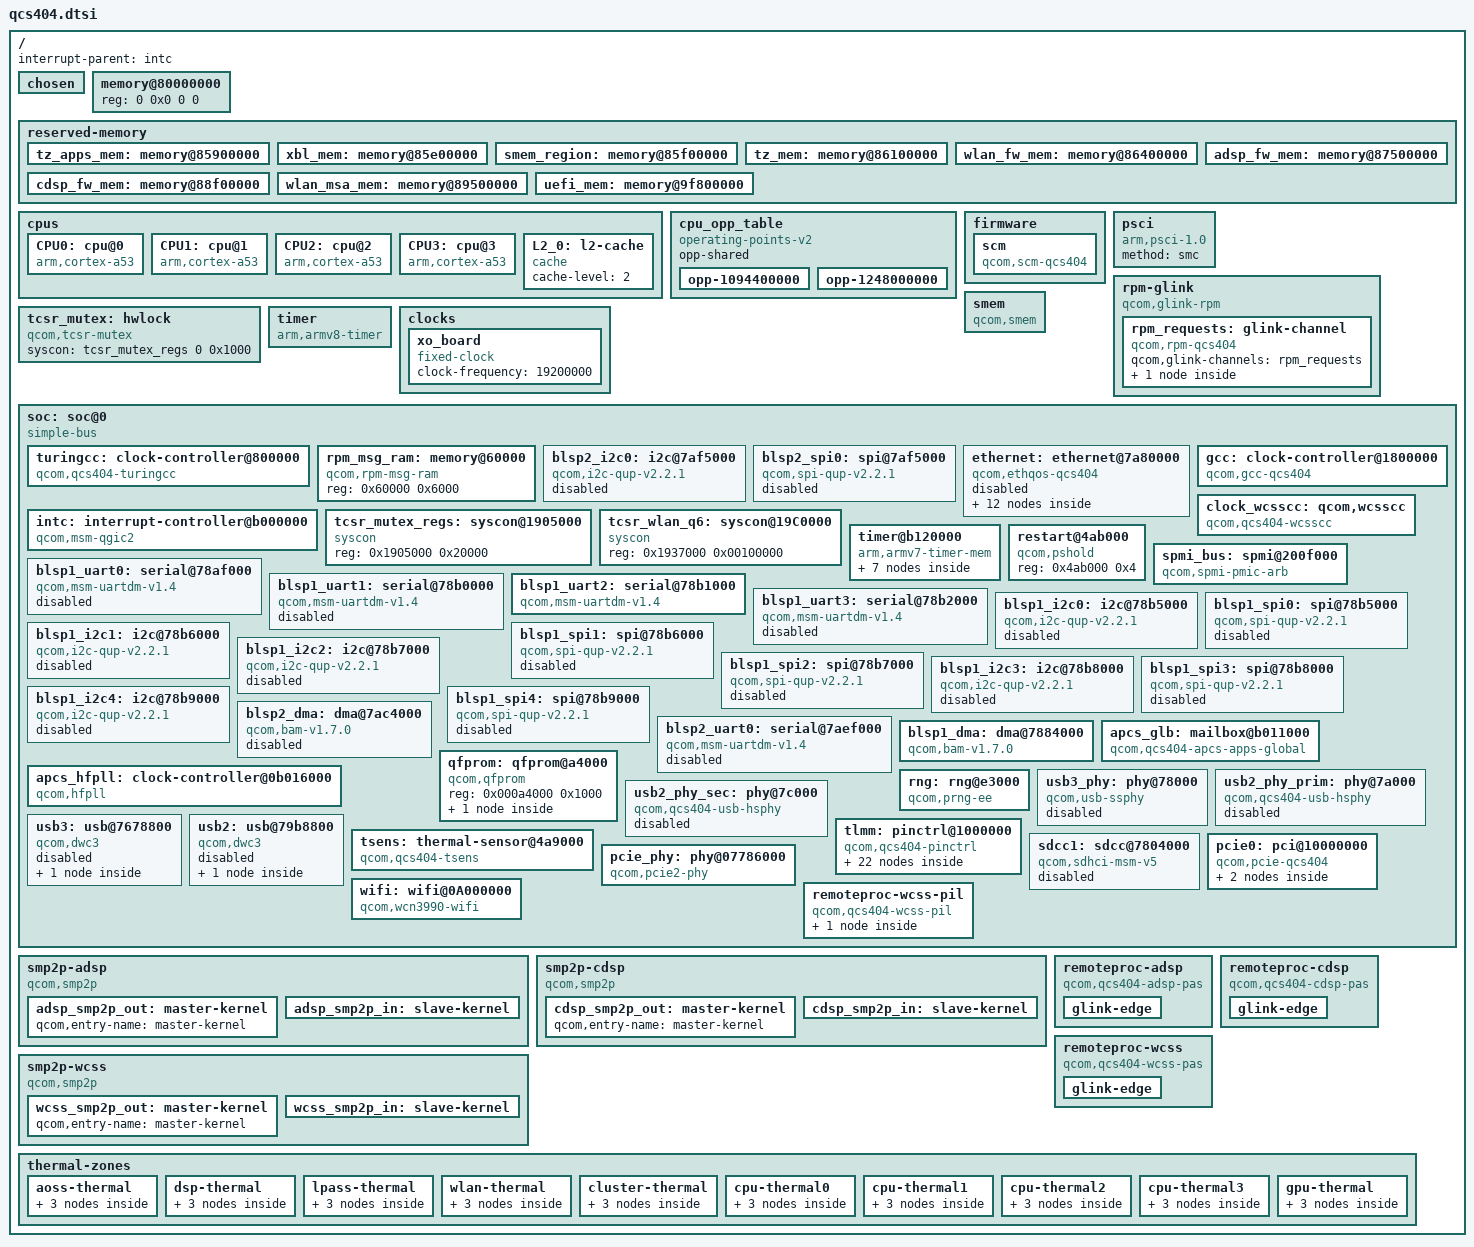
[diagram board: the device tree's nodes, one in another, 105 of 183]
// SPDX-License-Identifier: GPL-2.0
// Copyright (c) 2018, Linaro Limited

#include <dt-bindings/interrupt-controller/arm-gic.h>
#include <dt-bindings/clock/qcom,gcc-qcs404.h>
#include <dt-bindings/gpio/gpio.h>
#include <dt-bindings/clock/qcom,turingcc-qcs404.h>
#include <dt-bindings/clock/qcom,rpmcc.h>
#include <dt-bindings/clock/qcom,wcss-qcs404.h>

/ {
	interrupt-parent = <&intc>;

	#address-cells = <2>;
	#size-cells = <2>;

	chosen { };

	memory@80000000 {
		device_type = "memory";
		/* We expect the bootloader to fill in the reg */
		reg = <0 0x0 0 0>;
	};

	reserved-memory {
		#address-cells = <2>;
		#size-cells = <2>;
		ranges;

		tz_apps_mem: memory@85900000 {
			reg = <0 0x85900000 0 0x500000>;
			no-map;
		};

		xbl_mem: memory@85e00000 {
			reg = <0 0x85e00000 0 0x100000>;
			no-map;
		};

		smem_region: memory@85f00000 {
			reg = <0 0x85f00000 0 0x200000>;
			no-map;
		};

		tz_mem: memory@86100000 {
			reg = <0 0x86100000 0 0x300000>;
			no-map;
		};

		wlan_fw_mem: memory@86400000 {
			reg = <0 0x86400000 0 0x1100000>;
			no-map;
		};

		adsp_fw_mem: memory@87500000 {
			reg = <0 0x87500000 0 0x1a00000>;
			no-map;
		};

		cdsp_fw_mem: memory@88f00000 {
			reg = <0 0x88f00000 0 0x600000>;
			no-map;
		};

		wlan_msa_mem: memory@89500000 {
			reg = <0 0x89500000 0 0x100000>;
			no-map;
		};

		uefi_mem: memory@9f800000 {
			reg = <0 0x9f800000 0 0x800000>;
			no-map;
		};
	};

	cpus {
		#address-cells = <1>;
		#size-cells = <0>;

		CPU0: cpu@0 {
			device_type = "cpu";
			compatible = "arm,cortex-a53";
			reg = <0x100>;
			enable-method = "psci";
			next-level-cache = <&L2_0>;
			#cooling-cells= <2>;
			clocks = <&apcs_glb>;
			operating-points-v2 = <&cpu_opp_table>;
			cpu-supply = <&pms405_s3>;
		};

		CPU1: cpu@1 {
			device_type = "cpu";
			compatible = "arm,cortex-a53";
			reg = <0x101>;
			enable-method = "psci";
			next-level-cache = <&L2_0>;
			#cooling-cells= <2>;
			clocks = <&apcs_glb>;
			operating-points-v2 = <&cpu_opp_table>;
			cpu-supply = <&pms405_s3>;
		};

		CPU2: cpu@2 {
			device_type = "cpu";
			compatible = "arm,cortex-a53";
			reg = <0x102>;
			enable-method = "psci";
			next-level-cache = <&L2_0>;
			#cooling-cells= <2>;
			clocks = <&apcs_glb>;
			operating-points-v2 = <&cpu_opp_table>;
			cpu-supply = <&pms405_s3>;
		};

		CPU3: cpu@3 {
			device_type = "cpu";
			compatible = "arm,cortex-a53";
			reg = <0x103>;
			enable-method = "psci";
			next-level-cache = <&L2_0>;
			#cooling-cells= <2>;
			clocks = <&apcs_glb>;
			operating-points-v2 = <&cpu_opp_table>;
			cpu-supply = <&pms405_s3>;
		};

		L2_0: l2-cache {
			compatible = "cache";
			cache-level = <2>;
		};
	};

	cpu_opp_table: cpu_opp_table {
		compatible = "operating-points-v2";
		opp-shared;

		opp-1094400000 {
			opp-hz = /bits/ 64 <1094400000>;
			opp-microvolt = <1224000 1224000 1224000>;
		};
		opp-1248000000 {
			opp-hz = /bits/ 64 <1248000000>;
			opp-microvolt = <1288000 1288000 1288000>;
		};
	};

	firmware {
		scm: scm {
			compatible = "qcom,scm-qcs404", "qcom,scm";
			#reset-cells = <1>;
		};
	};

	psci {
		compatible = "arm,psci-1.0";
		method = "smc";
	};

	rpm-glink {
		compatible = "qcom,glink-rpm";

		interrupts = <GIC_SPI 168 IRQ_TYPE_EDGE_RISING>;
		qcom,rpm-msg-ram = <&rpm_msg_ram>;
		mboxes = <&apcs_glb 0>;

		rpm_requests: glink-channel {
			compatible = "qcom,rpm-qcs404";
			qcom,glink-channels = "rpm_requests";

			rpmcc: clock-controller {
				compatible = "qcom,rpmcc-qcs404";
				#clock-cells = <1>;
			};
		};
	};

	smem {
		compatible = "qcom,smem";

		memory-region = <&smem_region>;
		qcom,rpm-msg-ram = <&rpm_msg_ram>;

		hwlocks = <&tcsr_mutex 3>;
	};

	tcsr_mutex: hwlock {
		compatible = "qcom,tcsr-mutex";
		syscon = <&tcsr_mutex_regs 0 0x1000>;
		#hwlock-cells = <1>;
	};

	timer {
		compatible = "arm,armv8-timer";
		interrupts = <GIC_PPI 2 0xff08>,
			     <GIC_PPI 3 0xff08>,
			     <GIC_PPI 4 0xff08>,
			     <GIC_PPI 1 0xff08>;
	};

	clocks {
		xo_board: xo_board {
			compatible = "fixed-clock";
			#clock-cells = <0>;
			clock-frequency = <19200000>;
		};
	};

	soc: soc@0 {
		#address-cells = <1>;
		#size-cells = <1>;
		ranges = <0 0 0 0xffffffff>;
		compatible = "simple-bus";

		turingcc: clock-controller@800000 {
			compatible = "qcom,qcs404-turingcc";
			reg = <0x00800000 0x30000>;
			clocks = <&gcc GCC_CDSP_CFG_AHB_CLK>;

			#clock-cells = <1>;
			#reset-cells = <1>;
		};

		rpm_msg_ram: memory@60000 {
			compatible = "qcom,rpm-msg-ram";
			reg = <0x60000 0x6000>;
		};

		blsp2_i2c0: i2c@7af5000 {
			compatible = "qcom,i2c-qup-v2.2.1";
			reg = <0x07af5000 0x600>;
			interrupts = <GIC_SPI 299 IRQ_TYPE_LEVEL_HIGH>;
			clocks = <&gcc GCC_BLSP2_AHB_CLK>,
				<&gcc GCC_BLSP2_QUP0_I2C_APPS_CLK>;
			clock-names = "iface", "core";
			pinctrl-names = "default";
			pinctrl-0 = <&blsp2_i2c0_default>;
			#address-cells = <1>;
			#size-cells = <0>;
			status = "disabled";
		};

		blsp2_spi0: spi@7af5000 {
			compatible = "qcom,spi-qup-v2.2.1";
			reg = <0x07af5000 0x600>;
			interrupts = <GIC_SPI 299 IRQ_TYPE_LEVEL_HIGH>;
			clocks = <&gcc GCC_BLSP2_AHB_CLK>,
				<&gcc GCC_BLSP2_QUP0_SPI_APPS_CLK>;
			clock-names = "iface", "core";
			pinctrl-names = "default";
			pinctrl-0 = <&blsp2_spi0_default>;
			#address-cells = <1>;
			#size-cells = <0>;
			status = "disabled";
		};

		ethernet: ethernet@7a80000 {
			compatible = "qcom,ethqos-qcs404";
			reg = <0x07a80000 0x10000>,
			        <0x07a96000 0x100>;
			reg-names = "stmmaceth", "rgmii";
			clock-names = "stmmaceth", "pclk", "ptp_ref", "rgmii";
			clocks = <&gcc GCC_ETH_AXI_CLK>,
				<&gcc GCC_ETH_SLAVE_AHB_CLK>,
				<&gcc GCC_ETH_PTP_CLK>,
				<&gcc GCC_ETH_RGMII_CLK>;
			interrupts = <GIC_SPI 56 IRQ_TYPE_LEVEL_HIGH>,
					<GIC_SPI 55 IRQ_TYPE_LEVEL_HIGH>;
			interrupt-names = "macirq", "eth_lpi";

			snps,axi-config = <&stmmac_axi_setup>;
			snps,mtl-rx-config = <&mtl_rx_setup>;
			snps,mtl-tx-config = <&mtl_tx_setup>;

			snps,txpbl = <8>;
			snps,rxpbl = <2>;
			snps,aal;
			snps,tso;

			rx-fifo-depth = <4096>;
			tx-fifo-depth = <4096>;
			snps,force_sf_dma_mode;
			status = "disabled";

			stmmac_axi_setup: stmmac-axi-config {
				snps,rd_osr_lmt = <2>;
				snps,blen = <0 0 0 0 16 8 4>;
			};
			mtl_rx_setup: rx-queues-config {
				snps,rx-queues-to-use = <4>;
				snps,rx-sched-sp;
				queue0 {
					snps,dcb-algorithm;
					snps,map-to-dma-channel = <0x0>;
					snps,priority = <0x0>;
				};
				queue1 {
					snps,dcb-algorithm;
					snps,map-to-dma-channel = <0x1>;
					snps,priority = <0x1>;
				};
				queue2 {
					snps,dcb-algorithm;
					snps,map-to-dma-channel = <0x2>;
					snps,priority = <0x1>;
				};
				queue3 {
					snps,dcb-algorithm;
					snps,map-to-dma-channel = <0x3>;
					snps,priority = <0x1>;
				};
			};

			mtl_tx_setup: tx-queues-config {
				snps,tx-queues-to-use = <5>;
				snps,tx-sched-wrr;
				queue0 {
					snps,weight = <0x10>;
					snps,dcb-algorithm;
					snps,priority = <0x0>;
					snps,map-to-dma-channel = <0x0>;
				};
				queue1 {
					snps,weight = <0x10>;
					snps,dcb-algorithm;
					snps,priority = <0x1>;
					snps,map-to-dma-channel = <0x1>;
				};
				queue2 {
					snps,weight = <0x10>;
					snps,dcb-algorithm;
					snps,priority = <0x1>;
					snps,map-to-dma-channel = <0x2>;
				};
				queue3 {
					snps,weight = <0x10>;
					snps,dcb-algorithm;
					snps,priority = <0x1>;
					snps,map-to-dma-channel = <0x3>;
				};
				queue4 {
					snps,weight = <0x10>;
					snps,dcb-algorithm;
					snps,priority = <0x1>;
					snps,map-to-dma-channel = <0x4>;
				};
			};
		};

		intc: interrupt-controller@b000000 {
			compatible = "qcom,msm-qgic2";
			interrupt-controller;
			#interrupt-cells = <3>;
			reg = <0x0b000000 0x1000>,
			      <0x0b002000 0x1000>;
		};

		gcc: clock-controller@1800000 {
			compatible = "qcom,gcc-qcs404";
			reg = <0x1800000 0x80000>;
			#clock-cells = <1>;
			#reset-cells = <1>;

			assigned-clocks = <&gcc GCC_APSS_AHB_CLK_SRC>;
			assigned-clock-rates = <19200000>;
			qcom,wcss-protected;
		};

		clock_wcsscc: qcom,wcsscc {
			compatible = "qcom,qcs404-wcsscc";
			reg = <0x07500000 0x4e000>, <0x07550000 0x8012>, <0x07400000 0x104>;
			reg-names = "wcss_q6sstop", "wcnss_tcsr", "wcss_qdsp6ss";
			#clock-cells = <1>;
			#reset-cells = <1>;
		};

		tcsr_mutex_regs: syscon@1905000 {
			compatible = "syscon";
			reg = <0x1905000 0x20000>;
		};

		tcsr_wlan_q6: syscon@19C0000 {
			compatible = "syscon";
			reg = <0x1937000 0x00100000>;
		};

		timer@b120000 {
			#address-cells = <1>;
			#size-cells = <1>;
			ranges;
			compatible = "arm,armv7-timer-mem";
			reg = <0xb120000 0x1000>;
			clock-frequency = <19200000>;

			frame@b121000 {
				frame-number = <0>;
				interrupts = <GIC_SPI 8 IRQ_TYPE_LEVEL_HIGH>,
					     <GIC_SPI 7 IRQ_TYPE_LEVEL_HIGH>;
				reg = <0xb121000 0x1000>,
				      <0xb122000 0x1000>;
			};

			frame@b123000 {
				frame-number = <1>;
				interrupts = <GIC_SPI 9 IRQ_TYPE_LEVEL_HIGH>;
				reg = <0xb123000 0x1000>;
				status = "disabled";
			};

			frame@b124000 {
				frame-number = <2>;
				interrupts = <GIC_SPI 10 IRQ_TYPE_LEVEL_HIGH>;
				reg = <0xb124000 0x1000>;
				status = "disabled";
			};

			frame@b125000 {
				frame-number = <3>;
				interrupts = <GIC_SPI 11 IRQ_TYPE_LEVEL_HIGH>;
				reg = <0xb125000 0x1000>;
				status = "disabled";
			};

			frame@b126000 {
				frame-number = <4>;
				interrupts = <GIC_SPI 12 IRQ_TYPE_LEVEL_HIGH>;
				reg = <0xb126000 0x1000>;
				status = "disabled";
			};

			frame@b127000 {
				frame-number = <5>;
				interrupts = <GIC_SPI 13 IRQ_TYPE_LEVEL_HIGH>;
				reg = <0xb127000 0x1000>;
				status = "disabled";
			};

			frame@b128000 {
				frame-number = <6>;
				interrupts = <GIC_SPI 14 IRQ_TYPE_LEVEL_HIGH>;
				reg = <0xb128000 0x1000>;
				status = "disabled";
			};
		};

		restart@4ab000 {
			compatible = "qcom,pshold";
			reg = <0x4ab000 0x4>;
		};

		spmi_bus: spmi@200f000 {
			compatible = "qcom,spmi-pmic-arb";
			reg = <0x200f000 0x001000>,
			      <0x2400000 0x800000>,
			      <0x2c00000 0x800000>,
			      <0x3800000 0x200000>,
			      <0x200a000 0x002100>;
			reg-names = "core", "chnls", "obsrvr", "intr", "cnfg";
			interrupt-names = "periph_irq";
			interrupts = <GIC_SPI 190 IRQ_TYPE_LEVEL_HIGH>;
			qcom,ee = <0>;
			qcom,channel = <0>;
			#address-cells = <2>;
			#size-cells = <0>;
			interrupt-controller;
			#interrupt-cells = <4>;
		};

		blsp1_uart0: serial@78af000 {
			compatible = "qcom,msm-uartdm-v1.4", "qcom,msm-uartdm";
			reg = <0x078af000 0x200>;
			interrupts = <GIC_SPI 107 IRQ_TYPE_LEVEL_HIGH>;
			clocks = <&gcc GCC_BLSP1_UART0_APPS_CLK>, <&gcc GCC_BLSP1_AHB_CLK>;
			clock-names = "core", "iface";
			dmas = <&blsp1_dma 1>, <&blsp1_dma 0>;
			dma-names = "rx", "tx";
			pinctrl-names = "default";
			pinctrl-0 = <&blsp1_uart0_default>;
			status = "disabled";
		};

		blsp1_uart1: serial@78b0000 {
			compatible = "qcom,msm-uartdm-v1.4", "qcom,msm-uartdm";
			reg = <0x078b0000 0x200>;
			interrupts = <GIC_SPI 108 IRQ_TYPE_LEVEL_HIGH>;
			clocks = <&gcc GCC_BLSP1_UART1_APPS_CLK>, <&gcc GCC_BLSP1_AHB_CLK>;
			clock-names = "core", "iface";
			dmas = <&blsp1_dma 3>, <&blsp1_dma 2>;
			dma-names = "rx", "tx";
			pinctrl-names = "default";
			pinctrl-0 = <&blsp1_uart1_default>;
			status = "disabled";
		};

		blsp1_uart2: serial@78b1000 {
			compatible = "qcom,msm-uartdm-v1.4", "qcom,msm-uartdm";
			reg = <0x78b1000 0x200>;
			interrupts = <GIC_SPI 118 IRQ_TYPE_LEVEL_HIGH>;
			clocks = <&gcc GCC_BLSP1_UART2_APPS_CLK>, <&gcc GCC_BLSP1_AHB_CLK>;
			clock-names = "core", "iface";
			dmas = <&blsp1_dma 5>, <&blsp1_dma 4>;
			dma-names = "rx", "tx";
			pinctrl-names = "default";
			pinctrl-0 = <&blsp1_uart2_default>;
			status = "okay";
		};

		blsp1_uart3: serial@78b2000 {
			compatible = "qcom,msm-uartdm-v1.4", "qcom,msm-uartdm";
			reg = <0x078b2000 0x200>;
			interrupts = <GIC_SPI 119 IRQ_TYPE_LEVEL_HIGH>;
			clocks = <&gcc GCC_BLSP1_UART3_APPS_CLK>, <&gcc GCC_BLSP1_AHB_CLK>;
			clock-names = "core", "iface";
			dmas = <&blsp1_dma 7>, <&blsp1_dma 6>;
			dma-names = "rx", "tx";
			status = "disabled";
		};

		blsp1_i2c0: i2c@78b5000 {
			compatible = "qcom,i2c-qup-v2.2.1";
			reg = <0x078b5000 0x600>;
			interrupts = <GIC_SPI 95 IRQ_TYPE_LEVEL_HIGH>;
			clocks = <&gcc GCC_BLSP1_AHB_CLK>,
				<&gcc GCC_BLSP1_QUP0_I2C_APPS_CLK>;
			clock-names = "iface", "core";
			pinctrl-names = "default";
			pinctrl-0 = <&blsp1_i2c0_default>;
			#address-cells = <1>;
			#size-cells = <0>;
			status = "disabled";
		};

		blsp1_spi0: spi@78b5000 {
			compatible = "qcom,spi-qup-v2.2.1";
			reg = <0x078b5000 0x600>;
			interrupts = <GIC_SPI 95 IRQ_TYPE_LEVEL_HIGH>;
			clocks = <&gcc GCC_BLSP1_AHB_CLK>,
				<&gcc GCC_BLSP1_QUP0_SPI_APPS_CLK>;
			clock-names = "iface", "core";
			pinctrl-names = "default";
			pinctrl-0 = <&blsp1_spi0_default>;
			#address-cells = <1>;
			#size-cells = <0>;
			status = "disabled";
		};

		blsp1_i2c1: i2c@78b6000 {
			compatible = "qcom,i2c-qup-v2.2.1";
			reg = <0x078b6000 0x600>;
			interrupts = <GIC_SPI 96 IRQ_TYPE_LEVEL_HIGH>;
			clocks = <&gcc GCC_BLSP1_AHB_CLK>,
				<&gcc GCC_BLSP1_QUP1_I2C_APPS_CLK>;
			clock-names = "iface", "core";
			pinctrl-names = "default";
			pinctrl-0 = <&blsp1_i2c1_default>;
			#address-cells = <1>;
			#size-cells = <0>;
			status = "disabled";
		};

		blsp1_spi1: spi@78b6000 {
			compatible = "qcom,spi-qup-v2.2.1";
			reg = <0x078b6000 0x600>;
			interrupts = <GIC_SPI 96 IRQ_TYPE_LEVEL_HIGH>;
			clocks = <&gcc GCC_BLSP1_AHB_CLK>,
				<&gcc GCC_BLSP1_QUP1_SPI_APPS_CLK>;
			clock-names = "iface", "core";
			pinctrl-names = "default";
			pinctrl-0 = <&blsp1_spi1_default>;
			#address-cells = <1>;
			#size-cells = <0>;
			status = "disabled";
		};

		blsp1_i2c2: i2c@78b7000 {
			compatible = "qcom,i2c-qup-v2.2.1";
			reg = <0x078b7000 0x600>;
			interrupts = <GIC_SPI 97 IRQ_TYPE_LEVEL_HIGH>;
			clocks = <&gcc GCC_BLSP1_AHB_CLK>,
				<&gcc GCC_BLSP1_QUP2_I2C_APPS_CLK>;
			clock-names = "iface", "core";
			pinctrl-names = "default";
			pinctrl-0 = <&blsp1_i2c2_default>;
			#address-cells = <1>;
			#size-cells = <0>;
			status = "disabled";
		};

		blsp1_spi2: spi@78b7000 {
			compatible = "qcom,spi-qup-v2.2.1";
			reg = <0x078b7000 0x600>;
			interrupts = <GIC_SPI 97 IRQ_TYPE_LEVEL_HIGH>;
			clocks = <&gcc GCC_BLSP1_AHB_CLK>,
				<&gcc GCC_BLSP1_QUP2_SPI_APPS_CLK>;
			clock-names = "iface", "core";
			pinctrl-names = "default";
			pinctrl-0 = <&blsp1_spi2_default>;
			#address-cells = <1>;
			#size-cells = <0>;
			status = "disabled";
		};

		blsp1_i2c3: i2c@78b8000 {
			compatible = "qcom,i2c-qup-v2.2.1";
			reg = <0x078b8000 0x600>;
			interrupts = <GIC_SPI 98 IRQ_TYPE_LEVEL_HIGH>;
			clocks = <&gcc GCC_BLSP1_AHB_CLK>,
				<&gcc GCC_BLSP1_QUP3_I2C_APPS_CLK>;
			clock-names = "iface", "core";
			pinctrl-names = "default";
			pinctrl-0 = <&blsp1_i2c3_default>;
			#address-cells = <1>;
			#size-cells = <0>;
			status = "disabled";
		};

		blsp1_spi3: spi@78b8000 {
			compatible = "qcom,spi-qup-v2.2.1";
			reg = <0x078b8000 0x600>;
			interrupts = <GIC_SPI 98 IRQ_TYPE_LEVEL_HIGH>;
			clocks = <&gcc GCC_BLSP1_AHB_CLK>,
				<&gcc GCC_BLSP1_QUP3_SPI_APPS_CLK>;
			clock-names = "iface", "core";
			pinctrl-names = "default";
			pinctrl-0 = <&blsp1_spi3_default>;
			#address-cells = <1>;
			#size-cells = <0>;
			status = "disabled";
		};

		blsp1_i2c4: i2c@78b9000 {
			compatible = "qcom,i2c-qup-v2.2.1";
			reg = <0x078b9000 0x600>;
			interrupts = <GIC_SPI 99 IRQ_TYPE_LEVEL_HIGH>;
			clocks = <&gcc GCC_BLSP1_AHB_CLK>,
				<&gcc GCC_BLSP1_QUP4_I2C_APPS_CLK>;
			clock-names = "iface", "core";
			pinctrl-names = "default";
			pinctrl-0 = <&blsp1_i2c4_default>;
			#address-cells = <1>;
			#size-cells = <0>;
			status = "disabled";
		};

		blsp1_spi4: spi@78b9000 {
			compatible = "qcom,spi-qup-v2.2.1";
			reg = <0x078b9000 0x600>;
			interrupts = <GIC_SPI 99 IRQ_TYPE_LEVEL_HIGH>;
			clocks = <&gcc GCC_BLSP1_AHB_CLK>,
				<&gcc GCC_BLSP1_QUP4_SPI_APPS_CLK>;
			clock-names = "iface", "core";
			pinctrl-names = "default";
			pinctrl-0 = <&blsp1_spi4_default>;
			#address-cells = <1>;
			#size-cells = <0>;
			status = "disabled";
		};

		blsp2_dma: dma@7ac4000 {
			compatible = "qcom,bam-v1.7.0";
			reg = <0x07ac4000 0x17000>;
			interrupts = <GIC_SPI 239 IRQ_TYPE_LEVEL_HIGH>;
			clocks = <&gcc GCC_BLSP2_AHB_CLK>;
			clock-names = "bam_clk";
			#dma-cells = <1>;
			qcom,controlled-remotely = <1>;
			qcom,ee = <0>;
			status = "disabled";
		};

		blsp2_uart0: serial@7aef000 {
			compatible = "qcom,msm-uartdm-v1.4", "qcom,msm-uartdm";
			reg = <0x07aef000 0x200>;
			interrupts = <GIC_SPI 297 IRQ_TYPE_LEVEL_HIGH>;
			clocks = <&gcc GCC_BLSP2_UART0_APPS_CLK>, <&gcc GCC_BLSP2_AHB_CLK>;
			clock-names = "core", "iface";
			dmas = <&blsp2_dma 1>, <&blsp2_dma 0>;
			dma-names = "rx", "tx";
			pinctrl-names = "default";
			pinctrl-0 = <&blsp2_uart0_default>;
			status = "disabled";
		};

		blsp1_dma: dma@7884000 {
			compatible = "qcom,bam-v1.7.0";
			reg = <0x07884000 0x25000>;
			interrupts = <GIC_SPI 238 IRQ_TYPE_LEVEL_HIGH>;
			clocks = <&gcc GCC_BLSP1_AHB_CLK>;
			clock-names = "bam_clk";
			#dma-cells = <1>;
			qcom,controlled-remotely = <1>;
			qcom,ee = <0>;

			status = "okay";
		};

		apcs_glb: mailbox@b011000 {
			compatible = "qcom,qcs404-apcs-apps-global", "syscon";
			reg = <0xb011000 0x1000>;
			#mbox-cells = <1>;
			clocks = <&gcc GCC_GPLL0_AO_OUT_MAIN>, <&apcs_hfpll>;
			clock-names = "aux", "pll";
			#clock-cells = <0>;
		};

		apcs_hfpll: clock-controller@0b016000 {
			compatible = "qcom,hfpll";
			reg = <0x0b016000 0x30>;
			#clock-cells = <0>;
			clock-output-names = "apcs_hfpll";
			clocks = <&xo_board>;
			clock-names = "xo";
		};

		qfprom: qfprom@a4000 {
			compatible = "qcom,qfprom";
			reg = <0x000a4000 0x1000>;
			#address-cells = <1>;
			#size-cells = <1>;
			tsens_caldata: caldata@d0 {
				reg = <0x1f8 0x14>;
			};
		};

		rng: rng@e3000 {
			compatible = "qcom,prng-ee";
			reg = <0x000e3000 0x1000>;
			clocks = <&gcc GCC_PRNG_AHB_CLK>;
			clock-names = "core";
		};

		usb3_phy: phy@78000 {
			compatible = "qcom,usb-ssphy";
			reg = <0x78000 0x400>;
			#phy-cells = <0>;
			clocks = <&rpmcc RPM_SMD_LN_BB_CLK>,
				<&gcc GCC_USB_HS_PHY_CFG_AHB_CLK>,
				<&gcc GCC_USB3_PHY_PIPE_CLK>;
			clock-names = "ref", "phy", "pipe";
			resets = <&gcc GCC_USB3_PHY_BCR>,
				<&gcc GCC_USB3PHY_PHY_BCR>;
			reset-names = "com", "phy";
			status = "disabled";
		};

		usb2_phy_prim: phy@7a000 {
			compatible = "qcom,qcs404-usb-hsphy";
			reg = <0x7a000 0x200>;
			#phy-cells = <0>;
			clocks = <&rpmcc RPM_SMD_LN_BB_CLK>,
				<&gcc GCC_USB_HS_PHY_CFG_AHB_CLK>,
				<&gcc GCC_USB2A_PHY_SLEEP_CLK>;
			clock-names = "ref", "phy", "sleep";
			resets = <&gcc GCC_USB_HS_PHY_CFG_AHB_BCR>,
				<&gcc GCC_USB2A_PHY_BCR>;
			reset-names = "phy", "por";
			status = "disabled";
		};

		usb2_phy_sec: phy@7c000 {
			compatible = "qcom,qcs404-usb-hsphy";
			reg = <0x7c000 0x200>;
			#phy-cells = <0>;
			clocks = <&rpmcc RPM_SMD_LN_BB_CLK>,
				<&gcc GCC_USB_HS_PHY_CFG_AHB_CLK>,
				<&gcc GCC_USB2A_PHY_SLEEP_CLK>;
			clock-names = "ref", "phy", "sleep";
			resets = <&gcc GCC_QUSB2_PHY_BCR>,
				<&gcc GCC_USB2_HS_PHY_ONLY_BCR>;
			reset-names = "phy", "por";
			status = "disabled";
		};

		usb3: usb@7678800 {
			compatible = "qcom,dwc3";
			reg = <0x07678800 0x400>;
			#address-cells = <1>;
			#size-cells = <1>;
			ranges;
			clocks = <&gcc GCC_USB30_MASTER_CLK>,
				<&gcc GCC_SYS_NOC_USB3_CLK>,
				<&gcc GCC_USB30_SLEEP_CLK>,
				<&gcc GCC_USB30_MOCK_UTMI_CLK>;
			clock-names = "core", "iface", "sleep", "mock_utmi";
			assigned-clocks = <&gcc GCC_USB20_MOCK_UTMI_CLK>,
					<&gcc GCC_USB30_MASTER_CLK>;
			assigned-clock-rates = <19200000>, <200000000>;
			status = "disabled";

			dwc3@7580000 {
				compatible = "snps,dwc3";
				reg = <0x07580000 0xcd00>;
				interrupts = <GIC_SPI 26 IRQ_TYPE_LEVEL_HIGH>;
				phys = <&usb2_phy_sec>, <&usb3_phy>;
				phy-names = "usb2-phy", "usb3-phy";
				snps,has-lpm-erratum;
				snps,hird-threshold = /bits/ 8 <0x10>;
				snps,usb3_lpm_capable;
				dr_mode = "host";
			};
		};

		usb2: usb@79b8800 {
			compatible = "qcom,dwc3";
			reg = <0x079b8800 0x400>;
			#address-cells = <1>;
			#size-cells = <1>;
			ranges;
			clocks = <&gcc GCC_USB_HS_SYSTEM_CLK>,
				<&gcc GCC_PCNOC_USB2_CLK>,
				<&gcc GCC_USB_HS_INACTIVITY_TIMERS_CLK>,
				<&gcc GCC_USB20_MOCK_UTMI_CLK>;
			clock-names = "core", "iface", "sleep", "mock_utmi";
			assigned-clocks = <&gcc GCC_USB20_MOCK_UTMI_CLK>,
					<&gcc GCC_USB_HS_SYSTEM_CLK>;
			assigned-clock-rates = <19200000>, <133333333>;
			status = "disabled";

			dwc3@78c0000 {
				compatible = "snps,dwc3";
				reg = <0x078c0000 0xcc00>;
				interrupts = <GIC_SPI 44 IRQ_TYPE_LEVEL_HIGH>;
				phys = <&usb2_phy_prim>;
				phy-names = "usb2-phy";
				snps,has-lpm-erratum;
				snps,hird-threshold = /bits/ 8 <0x10>;
				snps,usb3_lpm_capable;
				dr_mode = "otg";
			};
		};

		tsens: thermal-sensor@4a9000 {
			compatible = "qcom,qcs404-tsens", "qcom,tsens-v1";
			reg = <0x004a9000 0x1000>, /* TM */
			      <0x004a8000 0x1000>; /* SROT */
			nvmem-cells = <&tsens_caldata>;
			nvmem-cell-names = "calib";
			#qcom,sensors = <10>;
			#thermal-sensor-cells = <1>;
		};

		tlmm: pinctrl@1000000 {
			compatible = "qcom,qcs404-pinctrl";
			reg = <0x01000000 0x200000>,
			      <0x01300000 0x200000>,
			      <0x07b00000 0x200000>;
			reg-names = "south", "north", "east";
			interrupts = <GIC_SPI 208 IRQ_TYPE_LEVEL_HIGH>;
			gpio-ranges = <&tlmm 0 0 120>;
			gpio-controller;
			#gpio-cells = <2>;
			interrupt-controller;
			#interrupt-cells = <2>;

			perst_state: perst {
				pins = "gpio43";
				function = "gpio";

				bias-pull-down;
				drive-strength = <2>;
				output-low;
			};

			pcie_dis_state: pcie-disable {
				pins = "gpio44";
				function = "gpio";

				bias-pull-down;
				drive-strength = <8>;
				output-low;
			};

			blsp1_i2c0_default: blsp1-i2c0-default {
				pins = "gpio32", "gpio33";
				function = "blsp_i2c0";
			};

			blsp1_i2c1_default: blsp1-i2c1-default {
				pins = "gpio24", "gpio25";
				function = "blsp_i2c1";
			};

			blsp1_i2c2_default: blsp1-i2c2-default {
				sda {
					pins = "gpio19";
					function = "blsp_i2c_sda_a2";
				};

				scl {
					pins = "gpio20";
					function = "blsp_i2c_scl_a2";
				};
			};

			blsp1_i2c3_default: blsp1-i2c3-default {
				pins = "gpio84", "gpio85";
				function = "blsp_i2c3";
			};

			blsp1_i2c4_default: blsp1-i2c4-default {
				pins = "gpio117", "gpio118";
				function = "blsp_i2c4";
			};

			blsp1_uart0_default: blsp1-uart0-default {
				pins = "gpio30", "gpio31", "gpio32", "gpio33";
				function = "blsp_uart0";
			};

			blsp1_uart1_default: blsp1-uart1-default {
				pins = "gpio22", "gpio23";
				function = "blsp_uart1";
			};

			blsp1_uart2_default: blsp1-uart2-default {
				rx {
					pins = "gpio18";
					function = "blsp_uart_rx_a2";
				};

				tx {
					pins = "gpio17";
					function = "blsp_uart_tx_a2";
				};
			};

			blsp2_i2c0_default: blsp2-i2c0-default {
				pins = "gpio28", "gpio29";
				function = "blsp_i2c5";
			};

			blsp1_spi0_default: blsp1-spi0-default {
				pins = "gpio30", "gpio31", "gpio32", "gpio33";
				function = "blsp_spi0";
			};

			blsp1_spi1_default: blsp1-spi1-default {
				pins = "gpio22", "gpio23", "gpio24", "gpio25";
				function = "blsp_spi1";
			};

			blsp1_spi2_default: blsp1-spi2-default {
				pins = "gpio17", "gpio18", "gpio19", "gpio20";
				function = "blsp_spi2";
			};

			blsp1_spi3_default: blsp1-spi3-default {
				pins = "gpio82", "gpio83", "gpio84", "gpio85";
				function = "blsp_spi3";
			};

			blsp1_spi4_default: blsp1-spi4-default {
				pins = "gpio37", "gpio38", "gpio117", "gpio118";
				function = "blsp_spi4";
			};

			blsp2_spi0_default: blsp2-spi0-default {
				pins = "gpio26", "gpio27", "gpio28", "gpio29";
				function = "blsp_spi5";
			};

			blsp2_uart0_default: blsp2-uart0-default {
				pins = "gpio26", "gpio27", "gpio28", "gpio29";
				function = "blsp_uart5";
			};
		};

		sdcc1: sdcc@7804000 {
			compatible = "qcom,sdhci-msm-v5";
			reg = <0x7804000 0x1000>, <0x7805000 0x1000>;
			reg-names = "hc_mem", "cmdq_mem";

			interrupts = <GIC_SPI 123 IRQ_TYPE_LEVEL_HIGH>,
				     <GIC_SPI 138 IRQ_TYPE_LEVEL_HIGH>;
			interrupt-names = "hc_irq", "pwr_irq";

			clocks = <&gcc GCC_SDCC1_APPS_CLK>,
				 <&gcc GCC_SDCC1_AHB_CLK>,
				 <&xo_board>;
			clock-names = "core", "iface", "xo";

			status = "disabled";
		};

		pcie0: pci@10000000 {
			compatible = "qcom,pcie-qcs404", "snps,dw-pcie";
			reg =  <0x10000000 0xf1d
				0x10000f20 0xa8
				0x07780000 0x2000
				0x10001000 0x2000>;
			reg-names = "dbi", "elbi", "parf", "config";
			device_type = "pci";
			linux,pci-domain = <0>;
			bus-range = <0x00 0xff>;
			num-lanes = <1>;
			#address-cells = <3>;
			#size-cells = <2>;

			ranges = <0x81000000 0 0          0x10003000 0 0x00010000   /* I/O */
				  0x82000000 0 0x10013000 0x10013000 0 0x007ed000>; /* memory */

			interrupts = <GIC_SPI 266 IRQ_TYPE_LEVEL_HIGH>;
			interrupt-names = "msi";
			#interrupt-cells = <1>;
			interrupt-map-mask = <0 0 0 0x7>;
			interrupt-map = <0 0 0 1 &intc GIC_SPI 68 IRQ_TYPE_LEVEL_HIGH>, /* int_a */
					<0 0 0 2 &intc GIC_SPI 224 IRQ_TYPE_LEVEL_HIGH>, /* int_b */
					<0 0 0 3 &intc GIC_SPI 267 IRQ_TYPE_LEVEL_HIGH>, /* int_c */
					<0 0 0 4 &intc GIC_SPI 268 IRQ_TYPE_LEVEL_HIGH>; /* int_d */
			clocks = <&gcc GCC_PCIE_0_AUX_CLK>,
			         <&gcc GCC_PCIE_0_MSTR_AXI_CLK>,
				 <&gcc GCC_PCIE_0_SLV_AXI_CLK>,
				 <&gcc GCC_PCIE_0_CFG_AHB_CLK>;
			clock-names = "aux", "master_bus", "slave_bus", "cfg";

			resets = <&gcc GCC_PCIE_0_AXI_MASTER_ARES>,
			         <&gcc GCC_PCIE_0_AXI_SLAVE_ARES>,
				 <&gcc GCC_PCIE_0_PIPE_ARES>,
				 // <&gcc >,
				 // <&gcc >,
				 // <&gcc >,
				 <&gcc GCC_PCIE_0_PHY_BCR>,
				 <&gcc GCC_PCIE_0_AXI_MASTER_STICKY_ARES>,
				 <&gcc GCC_PCIE_0_CORE_STICKY_ARES>,
				 <&gcc GCC_PCIE_0_BCR>,
				 <&gcc GCC_PCIE_0_AHB_ARES>,
				 <&gcc GCC_PCIEPHY_0_PHY_BCR>;
			reset-names = "axi_m",
				      "axi_s",
				      "pipe",
				      // "axi_m_vmid", no
				      // "axi_s_xpu", no
				      // "parf", no
				      "phy",
				      "axi_m_sticky",
				      "pipe_sticky", // core_sticky?
				      "pwr", // PCIE_0_BCR or SLEEP_ARES
				      "ahb",
				      "phy_ahb";

			phys = <&pcie_phy>;
			phy-names = "pciephy";

			perst-gpio = <&tlmm 43 GPIO_ACTIVE_LOW>;

			pinctrl-names = "default";
			pinctrl-0 = <&perst_state>, <&pcie_dis_state>;
			pcie@0 {
				reg = <0 0 0 0 0>;
				device_type = "pci";

				wifi@0,0 {
					reg = <0 0 0 0 0>;
				};
			};

//			status = "disabled";
		};

		pcie_phy: phy@07786000 {
			compatible = "qcom,pcie2-phy";
			reg = <0x07786000 0xb8>;

			clocks = <&gcc GCC_PCIE_0_PIPE_CLK>;
			clock-names = "pipe";

			resets = <&gcc GCC_PCIE_0_PIPE_ARES>;
			reset-names = "pipe";

			clock-output-names = "pcie_0_pipe_clk";
			#phy-cells = <0>;
		};

		wifi: wifi@0A000000 {
			compatible = "qcom,wcn3990-wifi";
			reg = <0x0A000000 0x800000>;
			reg-names = "membase";
			interrupts = <0 277 0 /* CE0 */ >,
				     <0 278 0 /* CE1 */ >,
				     <0 279 0 /* CE2 */ >,
				     <0 280 0 /* CE3 */ >,
				     <0 281 0 /* CE4 */ >,
				     <0 282 0 /* CE5 */ >,
				     <0 283 0 /* CE6 */ >,
				     <0 284 0 /* CE7 */ >,
				     <0 285 0 /* CE8 */ >,
				     <0 286 0 /* CE9 */ >,
				     <0 287 0 /* CE10 */ >,
				     <0 288 0 /* CE11 */ >;
			memory-region = <&wlan_msa_mem>;
		};

		remoteproc-wcss-pil {
			compatible = "qcom,qcs404-wcss-pil";
			reg = <0x07400000 0x00104>, <0x07500000 0x4e000>;
			reg-names = "qdsp6", "q6stop";

			interrupts-extended = <&intc GIC_SPI 153 IRQ_TYPE_EDGE_RISING>,
					      <&wcss_smp2p_in 0 IRQ_TYPE_EDGE_RISING>,
					      <&wcss_smp2p_in 1 IRQ_TYPE_EDGE_RISING>,
					      <&wcss_smp2p_in 2 IRQ_TYPE_EDGE_RISING>,
					      <&wcss_smp2p_in 3 IRQ_TYPE_EDGE_RISING>;
			interrupt-names = "wdog", "fatal", "ready",
					  "handover", "stop-ack";

			clocks = <&xo_board>,
				 <&gcc GCC_WCSS_Q6_AHB_CBCR_CLK>,
				 <&gcc GCC_WCSS_Q6_AXIM_CBCR_CLK>,
				 <&clock_wcsscc WCSS_AHBFABRIC_CBCR_CLK>,
				 <&clock_wcsscc WCSS_LCC_CBCR_CLK>,
				 <&clock_wcsscc WCSS_AHBS_CBCR_CLK>,
				 <&clock_wcsscc WCSS_TCM_CBCR_CLK>,
				 <&clock_wcsscc WCSS_AHBM_CBCR_CLK>,
				 <&clock_wcsscc WCSS_AXIM_CBCR_CLK>,
				 <&clock_wcsscc WCSS_QDSP6SS_XO_CBCR_CLK>,
				 <&clock_wcsscc WCSS_QDSP6SS_SLEEP_CBCR_CLK>,
				 <&clock_wcsscc WCSS_QDSP6SS_GFMMUX_CLK>,
				 <&clock_wcsscc WCSS_BCR_CBCR_CLK>;

			clock-names = "xo", "gcc_abhs_cbcr", "gcc_axim_cbcr",
				      "wcss_ahbfabric_cbcr", "wcnss_csr_cbcr",
				      "wcnss_ahbs_cbcr", "wcnss_tcm_slave_cbcr",
				      "wcnss_abhm_cbcr", "wcnss_axim_cbcr",
				      "wcnss_qdsp6ss_xo_cbcr", "wcnss_sleep_cbcr",
				      "wcnss_core_gfm", "wcss_bcr_cbcr";
			resets = <&gcc GCC_WDSP_RESTART>,
				 <&clock_wcsscc Q6SSTOP_QDSP6SS_RESET>,
				 <&clock_wcsscc Q6SSTOP_QDSP6SS_CORE_RESET>,
				 <&clock_wcsscc Q6SSTOP_QDSP6SS_BUS_RESET>,
				 <&clock_wcsscc Q6SSTOP_BCR_RESET>;
			reset-names = "wcss_reset", "wcss_q6_reset",
				      "wcss_q6_core_reset", "wcss_q6_bus_reset",
				      "wcss_q6_bcr_reset";

			memory-region = <&wlan_fw_mem>;

			qcom,smem-states = <&wcss_smp2p_out 0>;
			qcom,smem-state-names = "stop";
			qcom,halt-regs = <&tcsr_wlan_q6 0x18000>;
			glink-edge {
				interrupts = <GIC_SPI 156 IRQ_TYPE_EDGE_RISING>;
				#address-cells = <1>;
				#size-cells = <1>;
				qcom,remote-pid = <1>;
				mboxes = <&apcs_glb 16>;
				label = "wcss";
			};
		};
	};

	smp2p-adsp {
		compatible = "qcom,smp2p";
		qcom,smem = <443>, <429>;
		interrupts = <GIC_SPI 291 IRQ_TYPE_EDGE_RISING>;
		mboxes = <&apcs_glb 10>;
		qcom,local-pid = <0>;
		qcom,remote-pid = <2>;

		adsp_smp2p_out: master-kernel {
			qcom,entry-name = "master-kernel";
			#qcom,smem-state-cells = <1>;
		};

		adsp_smp2p_in: slave-kernel {
			qcom,entry-name = "slave-kernel";
			interrupt-controller;
			#interrupt-cells = <2>;
		};
	};

	smp2p-cdsp {
		compatible = "qcom,smp2p";
		qcom,smem = <94>, <432>;
		interrupts = <GIC_SPI 143 IRQ_TYPE_EDGE_RISING>;
		mboxes = <&apcs_glb 14>;
		qcom,local-pid = <0>;
		qcom,remote-pid = <5>;

		cdsp_smp2p_out: master-kernel {
			qcom,entry-name = "master-kernel";
			#qcom,smem-state-cells = <1>;
		};

		cdsp_smp2p_in: slave-kernel {
			qcom,entry-name = "slave-kernel";
			interrupt-controller;
			#interrupt-cells = <2>;
		};
	};

	smp2p-wcss {
		compatible = "qcom,smp2p";
		qcom,smem = <435>, <428>;
		interrupts = <GIC_SPI 158 IRQ_TYPE_EDGE_RISING>;
		mboxes = <&apcs_glb 18>;
		qcom,local-pid = <0>;
		qcom,remote-pid = <1>;

		wcss_smp2p_out: master-kernel {
			qcom,entry-name = "master-kernel";
			#qcom,smem-state-cells = <1>;
		};

		wcss_smp2p_in: slave-kernel {
			qcom,entry-name = "slave-kernel";
			interrupt-controller;
			#interrupt-cells = <2>;
		};
	};

	remoteproc-adsp {
		compatible = "qcom,qcs404-adsp-pas";

		interrupts-extended = <&intc GIC_SPI 293 IRQ_TYPE_EDGE_RISING>,
				      <&adsp_smp2p_in 0 IRQ_TYPE_EDGE_RISING>,
				      <&adsp_smp2p_in 1 IRQ_TYPE_EDGE_RISING>,
				      <&adsp_smp2p_in 2 IRQ_TYPE_EDGE_RISING>,
				      <&adsp_smp2p_in 3 IRQ_TYPE_EDGE_RISING>;
		interrupt-names = "wdog", "fatal", "ready",
				  "handover", "stop-ack";

		clocks = <&xo_board>;
		clock-names = "xo";

		memory-region = <&adsp_fw_mem>;

		qcom,smem-states = <&adsp_smp2p_out 0>;
		qcom,smem-state-names = "stop";

		glink-edge {
			interrupts = <GIC_SPI 289 IRQ_TYPE_EDGE_RISING>;

			qcom,remote-pid = <2>;
			mboxes = <&apcs_glb 8>;

			label = "adsp";
		};
	};

	remoteproc-cdsp {
		compatible = "qcom,qcs404-cdsp-pas";

		interrupts-extended = <&intc GIC_SPI 229 IRQ_TYPE_EDGE_RISING>,
				      <&cdsp_smp2p_in 0 IRQ_TYPE_EDGE_RISING>,
				      <&cdsp_smp2p_in 1 IRQ_TYPE_EDGE_RISING>,
				      <&cdsp_smp2p_in 2 IRQ_TYPE_EDGE_RISING>,
				      <&cdsp_smp2p_in 3 IRQ_TYPE_EDGE_RISING>;
		interrupt-names = "wdog", "fatal", "ready",
				  "handover", "stop-ack";

		clocks = <&xo_board>;
		clock-names = "xo";

		memory-region = <&cdsp_fw_mem>;

		qcom,smem-states = <&cdsp_smp2p_out 0>;
		qcom,smem-state-names = "stop";

		glink-edge {
			interrupts = <GIC_SPI 141 IRQ_TYPE_EDGE_RISING>;

			qcom,remote-pid = <5>;
			mboxes = <&apcs_glb 12>;

			label = "cdsp";
		};
	};

	remoteproc-wcss {
		compatible = "qcom,qcs404-wcss-pas";

		interrupts-extended = <&intc GIC_SPI 153 IRQ_TYPE_EDGE_RISING>,
				      <&wcss_smp2p_in 0 IRQ_TYPE_EDGE_RISING>,
				      <&wcss_smp2p_in 1 IRQ_TYPE_EDGE_RISING>,
				      <&wcss_smp2p_in 2 IRQ_TYPE_EDGE_RISING>,
				      <&wcss_smp2p_in 3 IRQ_TYPE_EDGE_RISING>;
		interrupt-names = "wdog", "fatal", "ready",
				  "handover", "stop-ack";

		clocks = <&xo_board>;
		clock-names = "xo";

		memory-region = <&wlan_fw_mem>;

		qcom,smem-states = <&wcss_smp2p_out 0>;
		qcom,smem-state-names = "stop";

		glink-edge {
			interrupts = <GIC_SPI 156 IRQ_TYPE_EDGE_RISING>;

			qcom,remote-pid = <1>;
			mboxes = <&apcs_glb 16>;

			label = "wcss";
		};
	};

	thermal-zones {
		aoss-thermal {
			polling-delay-passive = <250>;
			polling-delay = <1000>;

			thermal-sensors = <&tsens 0>;

			trips {
				aoss_alert: trip0 {
					temperature = <75000>;
					hysteresis = <2000>;
					type = "passive";
				};
				aoss_crit: trip1 {
					temperature = <95000>;
					hysteresis = <2000>;
					type = "critical";
				};
			};
		};

		dsp-thermal {
			polling-delay-passive = <250>;
			polling-delay = <1000>;

			thermal-sensors = <&tsens 1>;

			trips {
				dsp_alert: trip0 {
					temperature = <75000>;
					hysteresis = <2000>;
					type = "passive";
				};
				dsp_crit: trip1 {
					temperature = <95000>;
					hysteresis = <2000>;
					type = "critical";
				};
			};
		};

		lpass-thermal {
			polling-delay-passive = <250>;
			polling-delay = <1000>;

			thermal-sensors = <&tsens 2>;

			trips {
				lpass_alert: trip0 {
					temperature = <75000>;
					hysteresis = <2000>;
					type = "passive";
				};
				lpass_crit: trip1 {
					temperature = <95000>;
					hysteresis = <2000>;
					type = "critical";
				};
			};
		};

		wlan-thermal {
			polling-delay-passive = <250>;
			polling-delay = <1000>;

			thermal-sensors = <&tsens 3>;

			trips {
				wlan_alert: trip0 {
					temperature = <75000>;
					hysteresis = <2000>;
					type = "passive";
				};
				wlan_crit: trip1 {
					temperature = <95000>;
					hysteresis = <2000>;
					type = "critical";
				};
			};
		};

		cluster-thermal {
			polling-delay-passive = <250>;
			polling-delay = <1000>;

			thermal-sensors = <&tsens 4>;

			trips {
				cluster_alert: cluster_alert {
					temperature = <75000>;
					hysteresis = <2000>;
					type = "passive";
				};
				cluster_crit: cluster_crit {
					temperature = <110000>;
					hysteresis = <2000>;
					type = "critical";
				};
			};
		};

		cpu-thermal0 {
			polling-delay-passive = <250>;
			polling-delay = <1000>;

			thermal-sensors = <&tsens 5>;

			trips {
				cpu_alert0: cpu_alert0 {
					temperature = <75000>;
					hysteresis = <2000>;
					type = "passive";
				};
				cpu_crit0: cpu_crit0 {
					temperature = <110000>;
					hysteresis = <2000>;
					type = "critical";
				};
			};
		};

		cpu-thermal1 {
			polling-delay-passive = <250>;
			polling-delay = <1000>;

			thermal-sensors = <&tsens 6>;

			trips {
				cpu_alert1: trip0 {
					temperature = <75000>;
					hysteresis = <2000>;
					type = "passive";
				};
				cpu_crit1: trip1 {
					temperature = <110000>;
					hysteresis = <2000>;
					type = "critical";
				};
			};
		};

		cpu-thermal2 {
			polling-delay-passive = <250>;
			polling-delay = <1000>;

			thermal-sensors = <&tsens 7>;

			trips {
				cpu_alert2: trip0 {
					temperature = <75000>;
					hysteresis = <2000>;
					type = "passive";
				};
				cpu_crit2: trip1 {
					temperature = <110000>;
					hysteresis = <2000>;
					type = "critical";
				};
			};
		};

		cpu-thermal3 {
			polling-delay-passive = <250>;
			polling-delay = <1000>;

			thermal-sensors = <&tsens 8>;

			trips {
				cpu_alert3: trip0 {
					temperature = <75000>;
					hysteresis = <2000>;
					type = "passive";
				};
				cpu_crit3: trip1 {
					temperature = <110000>;
					hysteresis = <2000>;
					type = "critical";
				};
			};
		};

		gpu-thermal {
			polling-delay-passive = <250>;
			polling-delay = <1000>;

			thermal-sensors = <&tsens 9>;

			trips {
				gpu_alert: trip0 {
					temperature = <75000>;
					hysteresis = <2000>;
					type = "passive";
				};
				gpu_crit: trip1 {
					temperature = <95000>;
					hysteresis = <2000>;
					type = "critical";
				};
			};
		};
	};
};
